AUTOSAR XML (schema 314)
package /ComponentType
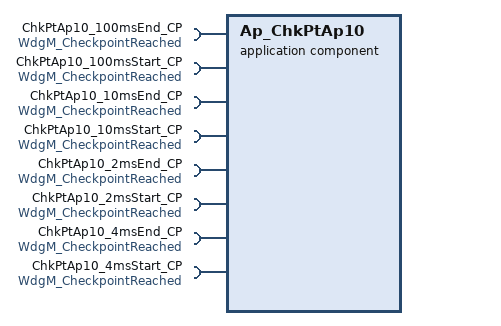
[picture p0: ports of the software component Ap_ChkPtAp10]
  application software component type Ap_ChkPtAp10
    8 x require port, all with client-com-spec=CheckpointReached, required-interface=WdgM_CheckpointReached:
      ChkPtAp10_100msEnd_CP
      ChkPtAp10_100msStart_CP
      ChkPtAp10_10msEnd_CP
      ChkPtAp10_10msStart_CP
      ChkPtAp10_2msEnd_CP
      ChkPtAp10_2msStart_CP
      ChkPtAp10_4msEnd_CP
      ChkPtAp10_4msStart_CP
  internal behavior Ap_ChkPtAp10_InternalBehavior: component=Ap_ChkPtAp10
    8 x timing event:
      TMT_ChkPtAp10_100msEnd_Per: start-on-event=ChkPtAp10_100msEnd_Per, period=0.1
      TMT_ChkPtAp10_100msStart_Per: start-on-event=ChkPtAp10_100msStart_Per, period=0.1
      TMT_ChkPtAp10_10msEnd_Per: start-on-event=ChkPtAp10_10msEnd_Per, period=0.01
      TMT_ChkPtAp10_10msStart_Per: start-on-event=ChkPtAp10_10msStart_Per, period=0.01
      TMT_ChkPtAp10_2msEnd_Per: start-on-event=ChkPtAp10_2msEnd_Per, period=0.002
      TMT_ChkPtAp10_2msStart_Per: start-on-event=ChkPtAp10_2msStart_Per, period=0.002
      TMT_ChkPtAp10_4msEnd_Per: start-on-event=ChkPtAp10_4msEnd_Per, period=0.004
      TMT_ChkPtAp10_4msStart_Per: start-on-event=ChkPtAp10_4msStart_Per, period=0.004
    port-api-options:
      enable-take-address=false, indirect-api=false, port=ChkPtAp10_100msEnd_CP
      enable-take-address=false, indirect-api=false, port=ChkPtAp10_100msStart_CP
      enable-take-address=false, indirect-api=false, port=ChkPtAp10_10msEnd_CP
      enable-take-address=false, indirect-api=false, port=ChkPtAp10_10msStart_CP
      enable-take-address=false, indirect-api=false, port=ChkPtAp10_2msEnd_CP
      enable-take-address=false, indirect-api=false, port=ChkPtAp10_2msStart_CP
      enable-take-address=false, indirect-api=false, port=ChkPtAp10_4msEnd_CP
      enable-take-address=false, indirect-api=false, port=ChkPtAp10_4msStart_CP
    8 x runnable:
      ChkPtAp10_100msEnd_Per
        sync call SC_ChkPtAp10_100msEnd_CP_CheckpointReached: operation=ChkPtAp10_100msEnd_CP.CheckpointReached, timeout=0
      ChkPtAp10_100msStart_Per
        sync call SC_ChkPtAp10_100msStart_CP_CheckpointReached: operation=ChkPtAp10_100msStart_CP.CheckpointReached, timeout=0
      ChkPtAp10_10msEnd_Per
        sync call SC_ChkPtAp10_10msEnd_CP_CheckpointReached: operation=ChkPtAp10_10msEnd_CP.CheckpointReached, timeout=0
      ChkPtAp10_10msStart_Per
        sync call SC_ChkPtAp10_10msStart_CP_CheckpointReached: operation=ChkPtAp10_10msStart_CP.CheckpointReached, timeout=0
      ChkPtAp10_2msEnd_Per
        sync call SC_ChkPtAp10_2msEnd_CP_CheckpointReached: operation=ChkPtAp10_2msEnd_CP.CheckpointReached, timeout=0
      ChkPtAp10_2msStart_Per
        sync call SC_ChkPtAp10_2msStart_CP_CheckpointReached: operation=ChkPtAp10_2msStart_CP.CheckpointReached, timeout=0
      ChkPtAp10_4msEnd_Per
        sync call SC_ChkPtAp10_4msEnd_CP_CheckpointReached: operation=ChkPtAp10_4msEnd_CP.CheckpointReached, timeout=0
      ChkPtAp10_4msStart_Per
        sync call SC_ChkPtAp10_4msStart_CP_CheckpointReached: operation=ChkPtAp10_4msStart_CP.CheckpointReached, timeout=0
  swc implementation Ap_ChkPtAp10_Implementation: behavior=Ap_ChkPtAp10_InternalBehavior
    code-descriptors:
      code Code: type=SRC
